# STM32WL5x_CM0P register map
File version: 1.5
CPU: CM0 r0p1, little endian, MPU, no FPU, 4 interrupt priority bits
Registers are 32-bit, read-write, reset 0x0 unless marked. A register's access mark holds for its fields unless they carry their own. Offsets are from the block's base; [hi:lo] are bit positions.

## COMP — Comparator
Base 0x40010200
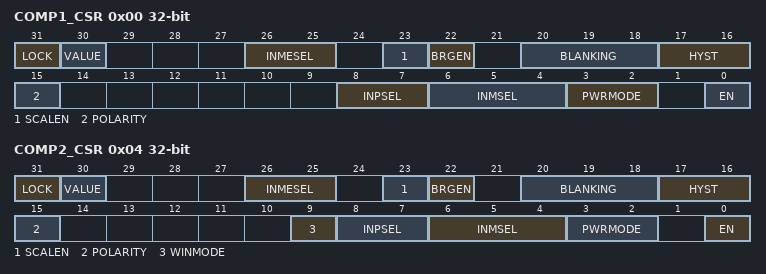
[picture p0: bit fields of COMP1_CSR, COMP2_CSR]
0x00 COMP1_CSR access per field
  [31] LOCK rw — COMP1_CSR register lock bit
  [30] VALUE ro — Comparator 1 output status bit
  [26:25] INMESEL rw — comparator 1 input minus extended selection bits.
  [23] SCALEN rw — Voltage scaler enable bit
  [22] BRGEN rw — Scaler bridge enable
  [20:18] BLANKING rw — Comparator 1 blanking source selection bits
  [17:16] HYST rw — Comparator 1 hysteresis selection bits
  [15] POLARITY rw — Comparator 1 polarity selection bit
  [8:7] INPSEL rw — Comparator1 input plus selection bit
  [6:4] INMSEL rw — Comparator 1 input minus selection bits
  [3:2] PWRMODE rw — Power Mode of the comparator 1
  [0] EN rw — Comparator 1 enable bit
0x04 COMP2_CSR access per field
  [31] LOCK rw — CSR register lock bit
  [30] VALUE ro — Comparator 2 output status bit
  [26:25] INMESEL rw — comparator 2 input minus extended selection bits.
  [23] SCALEN rw — Voltage scaler enable bit
  [22] BRGEN rw — Scaler bridge enable
  [20:18] BLANKING rw — Comparator 2 blanking source selection bits
  [17:16] HYST rw — Comparator 2 hysteresis selection bits
  [15] POLARITY rw — Comparator 2 polarity selection bit
  [9] WINMODE rw — Windows mode selection bit
  [8:7] INPSEL rw — Comparator 1 input plus selection bit
  [6:4] INMSEL rw — Comparator 2 input minus selection bits
  [3:2] PWRMODE rw — Power Mode of the comparator 2
  [0] EN rw — Comparator 2 enable bit

## CRC — Cyclic redundancy check calculation unit
Base 0x40023000
0x00 DR reset 0xFFFFFFFF — Data register
  [31:0] DR — Data register bits
0x04 IDR — Independent data register
  [31:0] IDR — General-purpose 32-bit data register bits
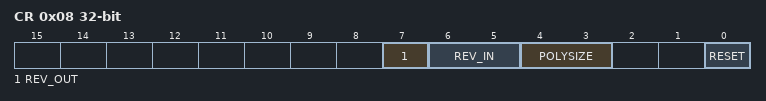
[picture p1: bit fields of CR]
0x08 CR — Control register
  [7] REV_OUT — Reverse output data
  [6:5] REV_IN — Reverse input data
  [4:3] POLYSIZE — Polynomial size
  [0] RESET — RESET bit
0x10 INIT reset 0xFFFFFFFF — Initial CRC value
  [31:0] CRC_INIT — Programmable initial CRC value
0x14 POL reset 0x4C11DB7 — polynomial
  [31:0] POL — Programmable polynomial

## DAC1 — Digital-to-analog converter
Base 0x40007400
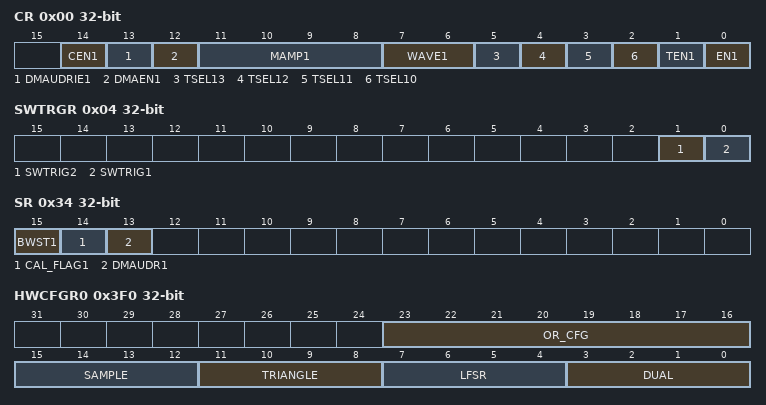
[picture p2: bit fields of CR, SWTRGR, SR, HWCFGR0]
0x00 CR — control register
  [14] CEN1 — DAC Channel 1 calibration enable
  [13] DMAUDRIE1 — DAC channel1 DMA Underrun Interrupt enable
  [12] DMAEN1 — DAC channel1 DMA enable
  [11:8] MAMP1 — DAC channel1 mask/amplitude selector
  [7:6] WAVE1 — DAC channel1 noise/triangle wave generation enable
  [5] TSEL13 — DAC channel1 trigger selection
  [4] TSEL12
  [3] TSEL11
  [2] TSEL10
  [1] TEN1 — DAC channel1 trigger enable
  [0] EN1 — DAC channel1 enable
0x04 SWTRGR access per field — software trigger register
  [1] SWTRIG2 rw
  [0] SWTRIG1 wo — DAC channel1 software trigger
0x08 DHR12R1 — channel1 12-bit right-aligned data holding register
  [11:0] DACC1DHR — DAC channel1 12-bit right-aligned data
0x0C DHR12L1 — channel1 12-bit left aligned data holding register
  [15:4] DACC1DHR — DAC channel1 12-bit left-aligned data
0x10 DHR8R1 — channel1 8-bit right aligned data holding register
  [7:0] DACC1DHR — DAC channel1 8-bit right-aligned data
0x20 DHR12RD — Dual DAC 12-bit right-aligned data holding register
  [11:0] DACC1DHR — DAC channel1 12-bit right-aligned data
0x24 DHR12LD — Dual DAC 12-bit left aligned data holding register
  [15:4] DACC1DHR — DAC channel1 12-bit left-aligned data
0x28 DHR8RD — Dual DAC 8-bit right aligned data holding register
  [7:0] DACC1DHR — DAC channel1 8-bit right-aligned data
0x2C DOR1 ro — DAC channel1 data output register
  [11:0] DACC1DOR
0x34 SR access per field — status register
  [15] BWST1 ro — DAC Channel 1 busy writing sample time flag
  [14] CAL_FLAG1 ro — DAC Channel 1 calibration offset status
  [13] DMAUDR1 rw — DAC channel1 DMA underrun flag
0x38 CCR — calibration control register
  [4:0] OTRIM1 — DAC Channel 1 offset trimming value
0x3C MCR — mode control register
  [2:0] MODE1 — DAC Channel 1 mode
0x40 SHSR1 — Sample and Hold sample time register 1
  [9:0] TSAMPLE1 — DAC Channel 1 sample Time (only valid in Sample and Hold mode)
0x44 SHSR2
  [9:0] TSAMPLE2
0x48 SHHR reset 0x10001 — Sample and Hold hold time register
  [9:0] THOLD1 — DAC Channel 1 hold Time (only valid in Sample and Hold mode)
0x4C SHRR reset 0x10001 — Sample and Hold refresh time register
  [7:0] TREFRESH1 — DAC Channel 1 refresh Time (only valid in Sample and Hold mode)
0x3F0 HWCFGR0 — Hardware Configuration Register
  [23:16] OR_CFG, [15:12] SAMPLE, [11:8] TRIANGLE, [7:4] LFSR, [3:0] DUAL
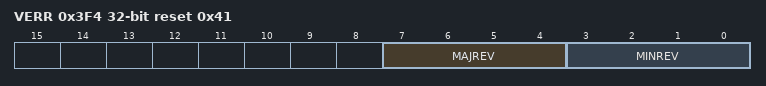
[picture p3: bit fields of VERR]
0x3F4 VERR ro reset 0x41 — Version Register
  [7:4] MAJREV — Major IP revision
  [3:0] MINREV — Minor IP revision
0x3F8 IPIDR ro reset 0x110011 — Identification Register
  [31:0] ID — IP identification code
0x3FC SIDR ro reset 0xA3C5DD01 — Size Identification Register
  [31:0] SID — Size and Identification register
